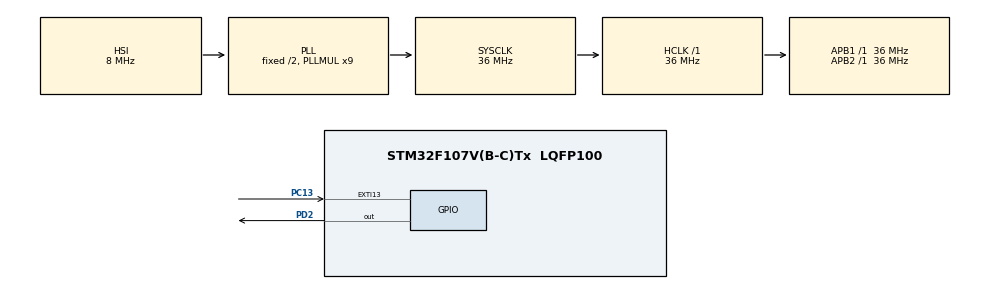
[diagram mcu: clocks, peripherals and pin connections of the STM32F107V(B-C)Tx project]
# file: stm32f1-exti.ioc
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Mcu.Family=STM32F1
PC13-TAMPER-RTC.Signal=GPXTI13
RCC.SYSCLKSource=RCC_SYSCLKSOURCE_PLLCLK
ProjectManager.StackSize=0x400
PA13.Signal=SYS_JTMS-SWDIO
ProjectManager.TargetToolchain=STM32CubeIDE
RCC.HCLKFreq_Value=36000000
RCC.APB2TimFreq_Value=36000000
RCC.USBFreq_Value=24000000
RCC.AHBFreq_Value=36000000
NVIC.EXTI15_10_IRQn=true\:0\:0\:false\:false\:true\:true\:true
board=custom
RCC.PLLMUL=RCC_PLL_MUL9
RCC.APB2Freq_Value=36000000
PA14.Mode=Serial_Wire
PA13.Mode=Serial_Wire
Mcu.Name=STM32F107V(B-C)Tx
RCC.SYSCLKFreq_VALUE=36000000
Mcu.Package=LQFP100
PC13-TAMPER-RTC.GPIO_PuPd=GPIO_PULLUP
PA14.Signal=SYS_JTCK-SWCLK
ProjectManager.HeapSize=0x200
NVIC.PriorityGroup=NVIC_PRIORITYGROUP_4
RCC.APB1TimFreq_Value=36000000
PD2.Signal=GPIO_Output
RCC.APB1Freq_Value=36000000

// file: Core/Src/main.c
/* USER CODE BEGIN Header */
/**
  ******************************************************************************
  * @file           : main.c
  * @brief          : Main program body
  ******************************************************************************
  * @attention
  *
  * <h2><center>&copy; Copyright (c) 2021 STMicroelectronics.
  * All rights reserved.</center></h2>
  *
  * This software component is licensed by ST under BSD 3-Clause license,
  * the "License"; You may not use this file except in compliance with the
  * License. You may obtain a copy of the License at:
  *                        opensource.org/licenses/BSD-3-Clause
  *
  ******************************************************************************
  */
/* USER CODE END Header */
#include "main.h"

/* USER CODE BEGIN PV */
volatile int flag_blink=0;
/* USER CODE END PV */

void SystemClock_Config(void);
static void MX_GPIO_Init(void);

/* USER CODE BEGIN 0 */
void HAL_GPIO_EXTI_Callback(uint16_t GPIO_Pin)
{
  /* Prevent unused argument(s) compilation warning */
  UNUSED(GPIO_Pin);
  if(GPIO_Pin==GPIO_PIN_13){
	  flag_blink=1;
  }
}
/* USER CODE END 0 */

int main(void)
{

  /* MCU Configuration--------------------------------------------------------*/

  /* Reset of all peripherals, Initializes the Flash interface and the Systick. */
  HAL_Init();

  /* Configure the system clock */
  SystemClock_Config();

  /* Initialize all configured peripherals */
  MX_GPIO_Init();

  /* Infinite loop */
  while (1)
  {
	  if(flag_blink==1){
		  HAL_Delay(250);
		  flag_blink=0;
		  HAL_GPIO_TogglePin(GPIOD, GPIO_PIN_2);
	  }
  }
}

void SystemClock_Config(void)
{
  RCC_OscInitTypeDef RCC_OscInitStruct = {0};
  RCC_ClkInitTypeDef RCC_ClkInitStruct = {0};

  /** Initializes the RCC Oscillators according to the specified parameters
  * in the RCC_OscInitTypeDef structure.
  */
  RCC_OscInitStruct.OscillatorType = RCC_OSCILLATORTYPE_HSI;
  RCC_OscInitStruct.HSIState = RCC_HSI_ON;
  RCC_OscInitStruct.HSICalibrationValue = RCC_HSICALIBRATION_DEFAULT;
  RCC_OscInitStruct.Prediv1Source = RCC_PREDIV1_SOURCE_HSE;
  RCC_OscInitStruct.PLL.PLLState = RCC_PLL_ON;
  RCC_OscInitStruct.PLL.PLLSource = RCC_PLLSOURCE_HSI_DIV2;
  RCC_OscInitStruct.PLL.PLLMUL = RCC_PLL_MUL9;
  RCC_OscInitStruct.PLL2.PLL2State = RCC_PLL_NONE;
  if (HAL_RCC_OscConfig(&RCC_OscInitStruct) != HAL_OK)
  {
    Error_Handler();
  }
  /** Initializes the CPU, AHB and APB buses clocks
  */
  RCC_ClkInitStruct.ClockType = RCC_CLOCKTYPE_HCLK|RCC_CLOCKTYPE_SYSCLK
                              |RCC_CLOCKTYPE_PCLK1|RCC_CLOCKTYPE_PCLK2;
  RCC_ClkInitStruct.SYSCLKSource = RCC_SYSCLKSOURCE_PLLCLK;
  RCC_ClkInitStruct.AHBCLKDivider = RCC_SYSCLK_DIV1;
  RCC_ClkInitStruct.APB1CLKDivider = RCC_HCLK_DIV1;
  RCC_ClkInitStruct.APB2CLKDivider = RCC_HCLK_DIV1;

  if (HAL_RCC_ClockConfig(&RCC_ClkInitStruct, FLASH_LATENCY_1) != HAL_OK)
  {
    Error_Handler();
  }
  /** Configure the Systick interrupt time
  */
  __HAL_RCC_PLLI2S_ENABLE();
}

static void MX_GPIO_Init(void)
{
  GPIO_InitTypeDef GPIO_InitStruct = {0};

  /* GPIO Ports Clock Enable */
  __HAL_RCC_GPIOC_CLK_ENABLE();
  __HAL_RCC_GPIOA_CLK_ENABLE();
  __HAL_RCC_GPIOD_CLK_ENABLE();

  /*Configure GPIO pin Output Level */
  HAL_GPIO_WritePin(GPIOD, GPIO_PIN_2, GPIO_PIN_RESET);

  /*Configure GPIO pin : PC13 */
  GPIO_InitStruct.Pin = GPIO_PIN_13;
  GPIO_InitStruct.Mode = GPIO_MODE_IT_RISING;
  GPIO_InitStruct.Pull = GPIO_PULLUP;
  HAL_GPIO_Init(GPIOC, &GPIO_InitStruct);

  /*Configure GPIO pin : PD2 */
  GPIO_InitStruct.Pin = GPIO_PIN_2;
  GPIO_InitStruct.Mode = GPIO_MODE_OUTPUT_PP;
  GPIO_InitStruct.Pull = GPIO_NOPULL;
  GPIO_InitStruct.Speed = GPIO_SPEED_FREQ_LOW;
  HAL_GPIO_Init(GPIOD, &GPIO_InitStruct);

  /* EXTI interrupt init*/
  HAL_NVIC_SetPriority(EXTI15_10_IRQn, 0, 0);
  HAL_NVIC_EnableIRQ(EXTI15_10_IRQn);

}

void Error_Handler(void)
{
  __disable_irq();
  while (1)
  {
  }
}

/************************ (C) COPYRIGHT STMicroelectronics *****END OF FILE****/
